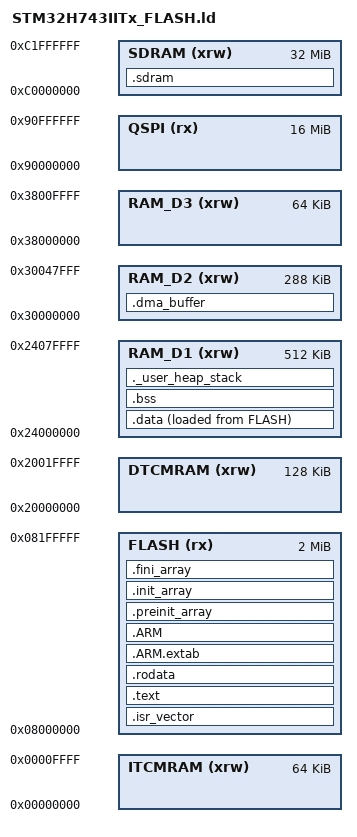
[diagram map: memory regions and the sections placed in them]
ENTRY(Reset_Handler)

_estack = ORIGIN(DTCMRAM) + LENGTH(DTCMRAM);

_Min_Heap_Size = 0x8000;
_Min_Stack_Size = 0x4000;

MEMORY
{
  DTCMRAM (xrw)  : ORIGIN = 0x20000000, LENGTH = 128K
  RAM_D1 (xrw)   : ORIGIN = 0x24000000, LENGTH = 512K
  RAM_D2 (xrw)   : ORIGIN = 0x30000000, LENGTH = 288K
  RAM_D3 (xrw)   : ORIGIN = 0x38000000, LENGTH = 64K
  ITCMRAM (xrw)  : ORIGIN = 0x00000000, LENGTH = 64K
  FLASH (rx)     : ORIGIN = 0x08000000, LENGTH = 2048K
  QSPI (rx)      : ORIGIN = 0x90000000, LENGTH = 16M
  SDRAM (xrw)    : ORIGIN = 0xC0000000, LENGTH = 32M
}

SECTIONS
{
  .isr_vector :
  {
    . = ALIGN(4);
    KEEP(*(.isr_vector))
    . = ALIGN(4);
  } >FLASH

  .text :
  {
    . = ALIGN(4);
    *(.text)
    *(.text*)
    *(.glue_7)
    *(.glue_7t)
    *(.eh_frame)

    KEEP (*(.init))
    KEEP (*(.fini))

    . = ALIGN(4);
    _etext = .;
  } >FLASH

  .rodata :
  {
    . = ALIGN(4);
    *(.rodata)
    *(.rodata*)
    . = ALIGN(4);
  } >FLASH

  .ARM.extab   : { *(.ARM.extab* .gnu.linkonce.armextab.*) } >FLASH
  .ARM : {
    __exidx_start = .;
    *(.ARM.exidx*)
    __exidx_end = .;
  } >FLASH

  .preinit_array     :
  {
    PROVIDE_HIDDEN (__preinit_array_start = .);
    KEEP (*(.preinit_array*))
    PROVIDE_HIDDEN (__preinit_array_end = .);
  } >FLASH

  .init_array :
  {
    PROVIDE_HIDDEN (__init_array_start = .);
    KEEP (*(SORT(.init_array.*)))
    KEEP (*(.init_array*))
    PROVIDE_HIDDEN (__init_array_end = .);
  } >FLASH

  .fini_array :
  {
    PROVIDE_HIDDEN (__fini_array_start = .);
    KEEP (*(SORT(.fini_array.*)))
    KEEP (*(.fini_array*))
    PROVIDE_HIDDEN (__fini_array_end = .);
  } >FLASH

  _sidata = LOADADDR(.data);

  .data : 
  {
    . = ALIGN(4);
    _sdata = .;
    *(.data)
    *(.data*)

    . = ALIGN(4);
    _edata = .;
  } >RAM_D1 AT> FLASH

  .bss :
  {
    _sbss = .;
    __bss_start__ = _sbss;
    *(.bss)
    *(.bss*)
    *(COMMON)

    . = ALIGN(4);
    _ebss = .;
    __bss_end__ = _ebss;
  } >RAM_D1

  ._user_heap_stack :
  {
    . = ALIGN(8);
    PROVIDE ( end = . );
    PROVIDE ( _end = . );
    . = . + _Min_Heap_Size;
    . = . + _Min_Stack_Size;
    . = ALIGN(8);
  } >RAM_D1

  /*
   * Верхняя граница для _sbrk (retarget.c). Куча newlib растёт от _end
   * вверх по RAM_D1; без границы malloc в обход heap_4 уезжал за конец
   * региона, и падало это не на malloc, а где-то потом на записи в мусорный
   * адрес. Граница = конец RAM_D1.
   */
  PROVIDE ( _heap_limit = ORIGIN(RAM_D1) + LENGTH(RAM_D1) );

  /*
   * DMA-буферы периферии (SDMMC, USART). Лежат в RAM_D2, который MPU
   * помечает как non-cacheable — иначе пришлось бы делать
   * SCB_CleanInvalidateDCache вокруг каждой транзакции.
   */
  .dma_buffer (NOLOAD) :
  {
    . = ALIGN(32);
    *(.dma_buffer)
    *(.dma_buffer*)
    . = ALIGN(32);
  } >RAM_D2

  /*
   * Секции в SDRAM: framebuffer'ы и арена модулей размещаются не линкером,
   * а в runtime (orca_memmap.h / orca_arena.c). Здесь только якорь, чтобы
   * линкер знал про регион и ругался при пересечении.
   */
  .sdram (NOLOAD) :
  {
    . = ALIGN(32);
    *(.sdram)
    *(.sdram*)
    . = ALIGN(32);
  } >SDRAM

  .ARM.attributes 0 : { *(.ARM.attributes) }
}
